# STM32F207 register map
File version: 1.0
CPU: CM3 r1p1, little endian, no MPU, no FPU, 4 interrupt priority bits
Registers are 32-bit, read-write, reset 0x0 unless marked. A register's access mark holds for its fields unless they carry their own. Offsets are from the block's base; [hi:lo] are bit positions; {n}, {i} and the like mark numbered series; 'fields as' and 'values as' point back to an identical list.

## Ethernet_PTP — Ethernet: Precision time protocol
Base 0x40028700
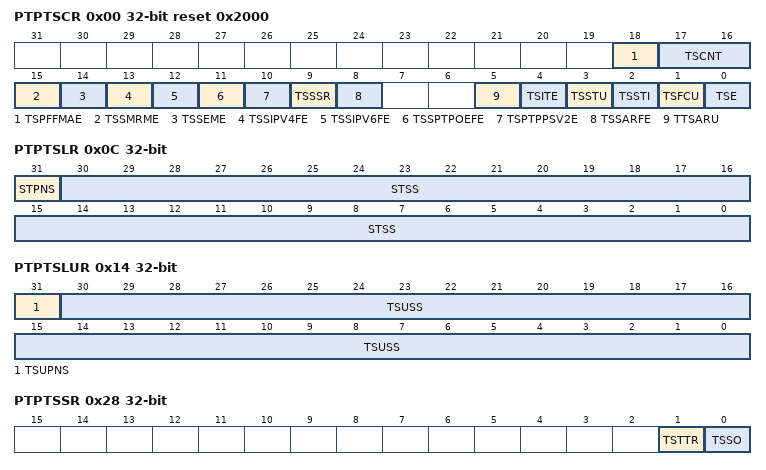
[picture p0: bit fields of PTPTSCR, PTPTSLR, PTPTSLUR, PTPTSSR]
0x00 PTPTSCR reset 0x2000 — Ethernet PTP time stamp control register
  [18] TSPFFMAE — Time stamp PTP frame filtering MAC address enable
  [17:16] TSCNT — Time stamp clock node type
  [15] TSSMRME — Time stamp snapshot for message relevant to master enable
  [14] TSSEME — Time stamp snapshot for event message enable
  [13] TSSIPV4FE — Time stamp snapshot for IPv4 frames enable
  [12] TSSIPV6FE — Time stamp snapshot for IPv6 frames enable
  [11] TSSPTPOEFE — Time stamp snapshot for PTP over ethernet frames enable
  [10] TSPTPPSV2E — Time stamp PTP packet snooping for version2 format enable
  [9] TSSSR — Time stamp subsecond rollover: digital or binary rollover control
  [8] TSSARFE — Time stamp snapshot for all received frames enable
  [5] TTSARU — Time stamp addend register update
  [4] TSITE — Time stamp interrupt trigger enable
  [3] TSSTU — Time stamp system time update
  [2] TSSTI — Time stamp system time initialize
  [1] TSFCU — Time stamp fine or coarse update
  [0] TSE — Time stamp enable
0x04 PTPSSIR — Ethernet PTP subsecond increment register
  [7:0] STSSI — System time subsecond increment
0x08 PTPTSHR ro — Ethernet PTP time stamp high register
  [31:0] STS — System time second
0x0C PTPTSLR ro — Ethernet PTP time stamp low register
  [31] STPNS — System time positive or negative sign
  [30:0] STSS — System time subseconds
0x10 PTPTSHUR — Ethernet PTP time stamp high update register
  [31:0] TSUS — Time stamp update second
0x14 PTPTSLUR — Ethernet PTP time stamp low update register
  [31] TSUPNS — Time stamp update positive or negative sign
  [30:0] TSUSS — Time stamp update subseconds
0x18 PTPTSAR — Ethernet PTP time stamp addend register
  [31:0] TSA — Time stamp addend
0x1C PTPTTHR — Ethernet PTP target time high register
  [31:0] TTSH — Target time stamp high
0x20 PTPTTLR — Ethernet PTP target time low register
  [31:0] TTSL — Target time stamp low
0x28 PTPTSSR ro — Ethernet PTP time stamp status register
  [1] TSTTR — Time stamp target time reached
  [0] TSSO — Time stamp second overflow
0x2C PTPPPSCR ro — Ethernet PTP PPS control register
  [3:0] PPSFREQ — PPS frequency selection

## OTG_FS_HOST — USB on the go full speed
Base 0x50000400
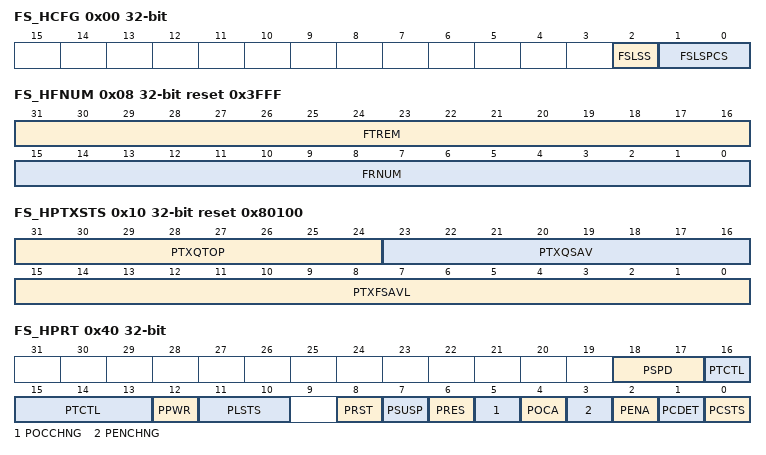
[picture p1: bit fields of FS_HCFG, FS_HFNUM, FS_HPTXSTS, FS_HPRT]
0x00 FS_HCFG access per field — OTG_FS host configuration register (OTG_FS_HCFG)
  [2] FSLSS ro — FS- and LS-only support
  [1:0] FSLSPCS rw — FS/LS PHY clock select
0x04 HFIR reset 0xEA60 — OTG_FS Host frame interval register
  [15:0] FRIVL — Frame interval
0x08 FS_HFNUM ro reset 0x3FFF — OTG_FS host frame number/frame time remaining register (OTG_FS_HFNUM)
  [31:16] FTREM — Frame time remaining
  [15:0] FRNUM — Frame number
0x10 FS_HPTXSTS access per field reset 0x80100 — OTG_FS_Host periodic transmit FIFO/queue status register (OTG_FS_HPTXSTS)
  [31:24] PTXQTOP ro — Top of the periodic transmit request queue
  [23:16] PTXQSAV ro — Periodic transmit request queue space available
  [15:0] PTXFSAVL rw — Periodic transmit data FIFO space available
0x14 HAINT ro — OTG_FS Host all channels interrupt register
  [15:0] HAINT — Channel interrupts
0x18 HAINTMSK — OTG_FS host all channels interrupt mask register
  [15:0] HAINTM — Channel interrupt mask
0x40 FS_HPRT access per field — OTG_FS host port control and status register (OTG_FS_HPRT)
  [18:17] PSPD ro — Port speed
  [16:13] PTCTL rw — Port test control
  [12] PPWR rw — Port power
  [11:10] PLSTS ro — Port line status
  [8] PRST rw — Port reset
  [7] PSUSP rw — Port suspend
  [6] PRES rw — Port resume
  [5] POCCHNG rw — Port overcurrent change
  [4] POCA ro — Port overcurrent active
  [3] PENCHNG rw — Port enable/disable change
  [2] PENA rw — Port enable
  [1] PCDET rw — Port connect detected
  [0] PCSTS ro — Port connect status
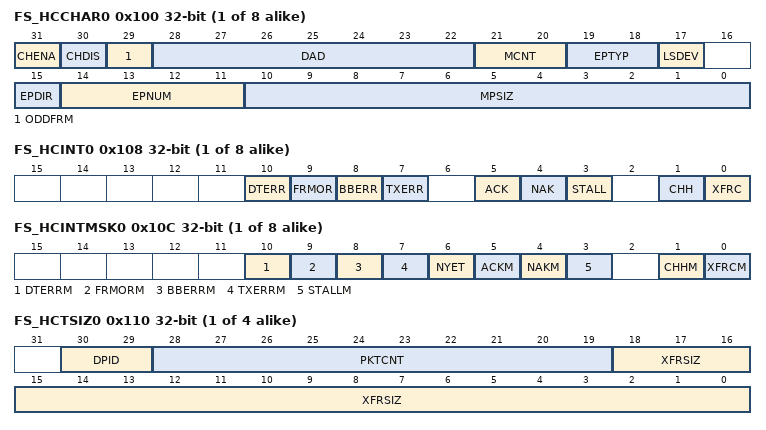
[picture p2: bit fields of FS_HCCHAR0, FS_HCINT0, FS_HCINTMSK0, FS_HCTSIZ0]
{0x100+0x20*i} FS_HCCHAR{i} (i=0..7) — OTG_FS host channel-{i} characteristics register (OTG_FS_HCCHAR{i})
  [31] CHENA — Channel enable
  [30] CHDIS — Channel disable
  [29] ODDFRM — Odd frame
  [28:22] DAD — Device address
  [21:20] MCNT — Multicount
  [19:18] EPTYP — Endpoint type
  [17] LSDEV — Low-speed device
  [15] EPDIR — Endpoint direction
  [14:11] EPNUM — Endpoint number
  [10:0] MPSIZ — Maximum packet size
{0x108+0x20*i} FS_HCINT{i} (i=0..7) — OTG_FS host channel-{i} interrupt register (OTG_FS_HCINT{i})
  [10] DTERR — Data toggle error
  [9] FRMOR — Frame overrun
  [8] BBERR — Babble error
  [7] TXERR — Transaction error
  [5] ACK — ACK response received/transmitted interrupt
  [4] NAK — NAK response received interrupt
  [3] STALL — STALL response received interrupt
  [1] CHH — Channel halted
  [0] XFRC — Transfer completed
{0x10C+0x20*i} FS_HCINTMSK{i} (i=0..7) — OTG_FS host channel-{i} mask register (OTG_FS_HCINTMSK{i})
  [10] DTERRM — Data toggle error mask
  [9] FRMORM — Frame overrun mask
  [8] BBERRM — Babble error mask
  [7] TXERRM — Transaction error mask
  [6] NYET — response received interrupt mask
  [5] ACKM — ACK response received/transmitted interrupt mask
  [4] NAKM — NAK response received interrupt mask
  [3] STALLM — STALL response received interrupt mask
  [1] CHHM — Channel halted mask
  [0] XFRCM — Transfer completed mask
{0x110+0x20*i} FS_HCTSIZ{i} (i=0..3) — OTG_FS host channel-{i} transfer size register
  [30:29] DPID — Data PID
  [28:19] PKTCNT — Packet count
  [18:0] XFRSIZ — Transfer size
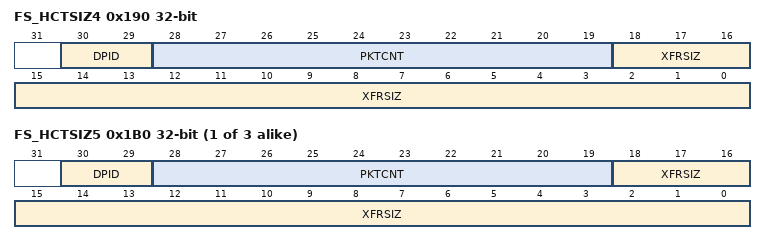
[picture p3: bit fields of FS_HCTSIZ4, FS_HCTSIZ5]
0x190 FS_HCTSIZ4 — OTG_FS host channel-x transfer size register
  fields as FS_HCTSIZ0
{0x110+0x20*i} FS_HCTSIZ{i} (i=5..7) — OTG_FS host channel-{i} transfer size register
  fields as FS_HCTSIZ0

## OTG_FS_PWRCLK — USB on the go full speed
Base 0x50000E00
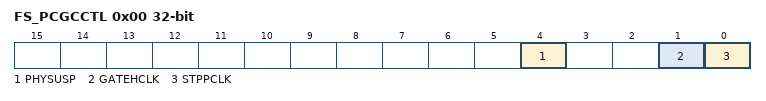
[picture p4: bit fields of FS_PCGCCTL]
0x00 FS_PCGCCTL — OTG_FS power and clock gating control register (OTG_FS_PCGCCTL)
  [4] PHYSUSP — PHY Suspended
  [1] GATEHCLK
  [0] STPPCLK — Stop PHY clock

## EXTI — External interrupt/event controller
Base 0x40013C00
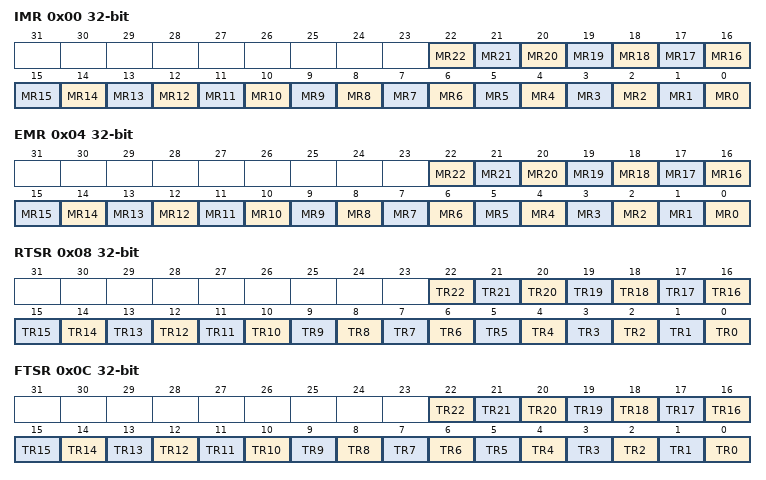
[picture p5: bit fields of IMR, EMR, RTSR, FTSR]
0x00 IMR — Interrupt mask register (EXTI_IMR)
  [n] MR{n} (n=0..22) — Interrupt Mask on line {n}
0x04 EMR — Event mask register (EXTI_EMR)
  [n] MR{n} (n=0..22) — Event Mask on line {n}
0x08 RTSR — Rising Trigger selection register (EXTI_RTSR)
  [n] TR{n} (n=0..22) — Rising trigger event configuration of line {n}
0x0C FTSR — Falling Trigger selection register (EXTI_FTSR)
  [n] TR{n} (n=0..22) — Falling trigger event configuration of line {n}
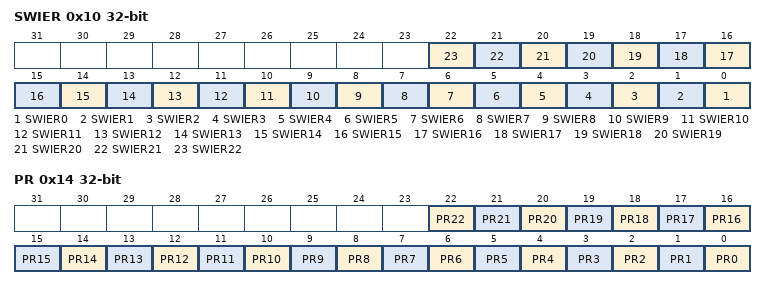
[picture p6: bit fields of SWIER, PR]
0x10 SWIER — Software interrupt event register (EXTI_SWIER)
  [n] SWIER{n} (n=0..22) — Software Interrupt on line {n}
0x14 PR — Pending register (EXTI_PR)
  [n] PR{n} (n=0..22) — Pending bit {n}

## FLASH
Base 0x40023C00
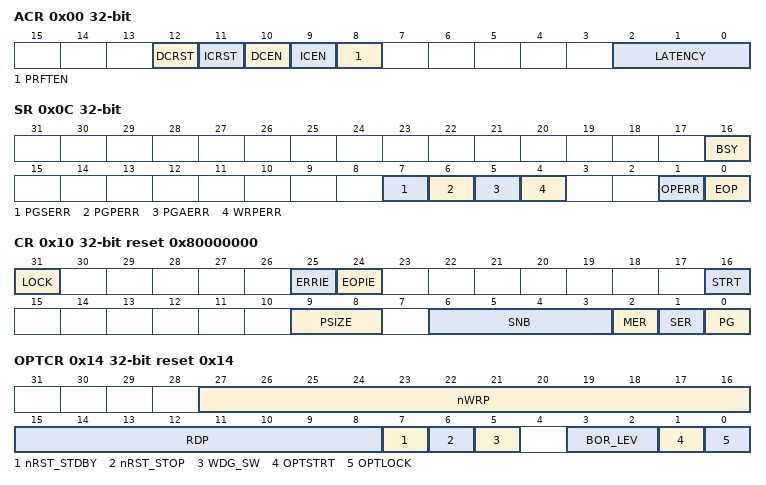
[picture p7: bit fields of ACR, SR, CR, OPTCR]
0x00 ACR access per field — Flash access control register
  [12] DCRST rw — Data cache reset
  [11] ICRST wo — Instruction cache reset
  [10] DCEN rw — Data cache enable
  [9] ICEN rw — Instruction cache enable
  [8] PRFTEN rw — Prefetch enable
  [2:0] LATENCY rw
0x04 KEYR wo — Flash key register
  [31:0] KEY — FPEC key
0x08 OPTKEYR wo — Flash option key register
  [31:0] OPTKEY — Option byte key
0x0C SR access per field — Status register
  [16] BSY ro — Busy
  [7] PGSERR rw — Programming sequence error
  [6] PGPERR rw — Programming parallelism error
  [5] PGAERR rw — Programming alignment error
  [4] WRPERR rw — Write protection error
  [1] OPERR rw — Operation error
  [0] EOP rw — End of operation
0x10 CR reset 0x80000000 — Control register
  [31] LOCK
  [25] ERRIE — Error interrupt enable
  [24] EOPIE — End of operation interrupt enable
  [16] STRT — Start
  [9:8] PSIZE — Program size
  [6:3] SNB — Sector number
  [2] MER — Mass Erase
  [1] SER — Sector Erase
  [0] PG — Programming
0x14 OPTCR reset 0x14 — Flash option control register
  [27:16] nWRP — Not write protect
  [15:8] RDP — Read protect
  [7] nRST_STDBY — nRST_STDBY User option bytes
  [6] nRST_STOP — nRST_STOP User option bytes
  [5] WDG_SW — WDG_SW User option bytes
  [3:2] BOR_LEV — BOR reset Level
  [1] OPTSTRT — Option start
  [0] OPTLOCK — Option lock

## OTG_HS_PWRCLK — USB on the go high speed
Base 0x40040E00
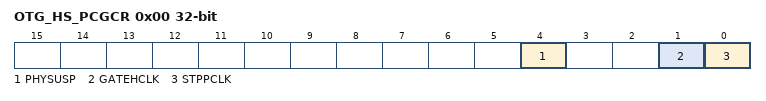
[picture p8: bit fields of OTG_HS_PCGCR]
0x00 OTG_HS_PCGCR — Power and clock gating control register
  [4] PHYSUSP — PHY suspended
  [1] GATEHCLK
  [0] STPPCLK — Stop PHY clock

## NVIC — Nested Vectored Interrupt Controller
Base 0xE000E000
0x04 ICTR ro — Interrupt Controller Type Register
  [3:0] INTLINESNUM — Total number of interrupt lines in groups
{0x100+4i} ISER{i} (i=0..2) — Interrupt Set-Enable Register
  [31:0] SETENA
{0x180+4i} ICER{i} (i=0..2) — Interrupt Clear-Enable Register
  [31:0] CLRENA
{0x200+4i} ISPR{i} (i=0..2) — Interrupt Set-Pending Register
  [31:0] SETPEND
{0x280+4i} ICPR{i} (i=0..2) — Interrupt Clear-Pending Register
  [31:0] CLRPEND
{0x300+4i} IABR{i} ro (i=0..2) — Interrupt Active Bit Register
  [31:0] ACTIVE
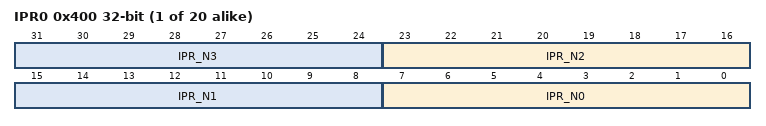
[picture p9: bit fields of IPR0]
{0x400+4i} IPR{i} (i=0..19) — Interrupt Priority Register
  [8n+7:8n] IPR_N{n} (n=0..3)
0xF00 STIR wo — Software Triggered Interrupt Register
  [8:0] INTID — interrupt to be triggered
